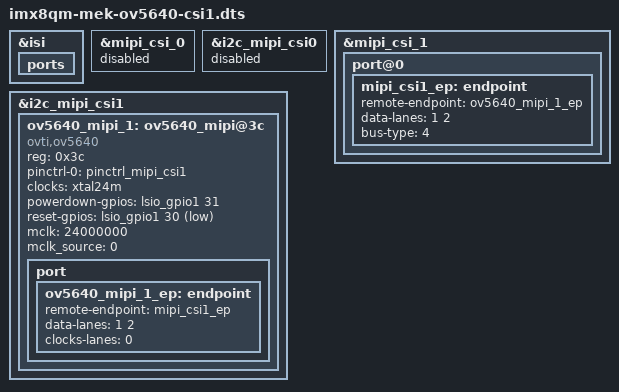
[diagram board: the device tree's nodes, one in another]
// SPDX-License-Identifier: GPL-2.0+
// Copyright NXP 2024

#include "imx8qm-mek.dts"

&isi {
	ports {
		/delete-node/port@2;
	};
};

&mipi_csi_0 {
	status = "disabled";
	/delete-node/port@0;
	/delete-node/port@1;
};

&i2c_mipi_csi0 {
	status = "disabled";
	/delete-node/max9286_mipi@6a;
};

&mipi_csi_1 {
	/delete-property/virtual-channel;

	/* Camera 1  MIPI CSI-2 (CSIS0) */
	port@0 {
		mipi_csi1_ep: endpoint {
			remote-endpoint = <&ov5640_mipi_1_ep>;
			data-lanes = <1 2>;
			bus-type = <4>;
		};
	};
};

&i2c_mipi_csi1 {
	ov5640_mipi_1: ov5640_mipi@3c {
		compatible = "ovti,ov5640";
		reg = <0x3c>;
		pinctrl-names = "default";
		pinctrl-0 = <&pinctrl_mipi_csi1>;
		clocks = <&xtal24m>;
		clock-names = "xclk";
		powerdown-gpios = <&lsio_gpio1 31 GPIO_ACTIVE_HIGH>;
		reset-gpios = <&lsio_gpio1 30 GPIO_ACTIVE_LOW>;
		mclk = <24000000>;
		mclk_source = <0>;
		status = "okay";
		port {
			ov5640_mipi_1_ep: endpoint {
				remote-endpoint = <&mipi_csi1_ep>;
				data-lanes = <1 2>;
				clocks-lanes = <0>;
			};
		};
	};

	/delete-node/max9286_mipi@6a;
};
